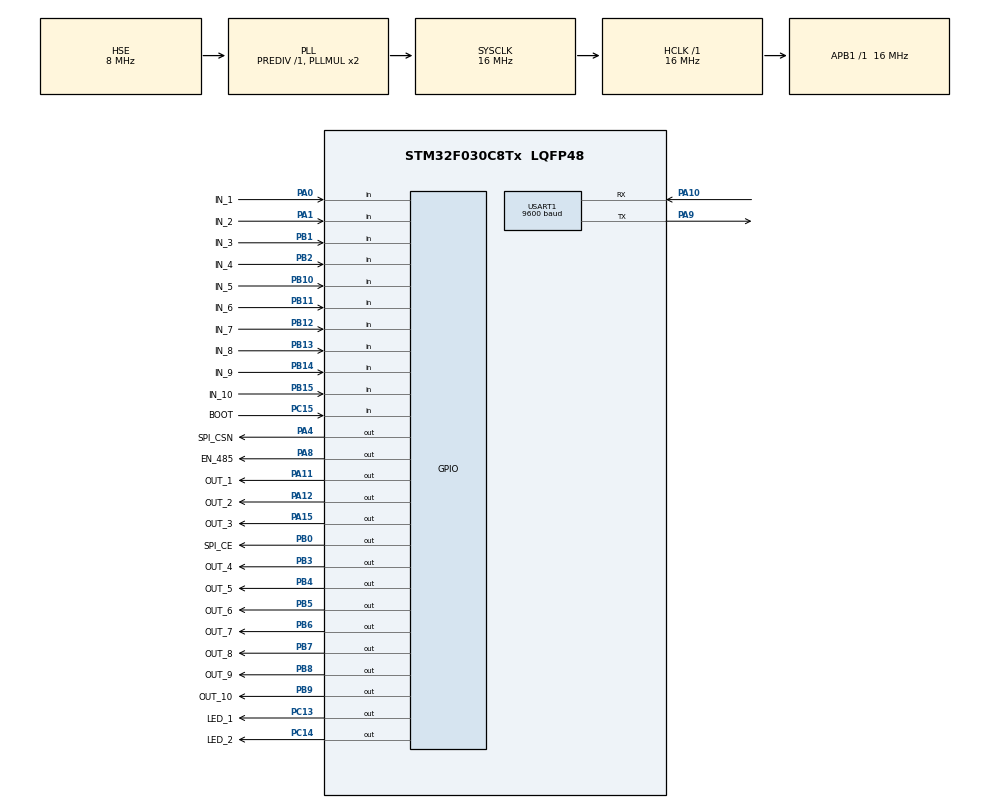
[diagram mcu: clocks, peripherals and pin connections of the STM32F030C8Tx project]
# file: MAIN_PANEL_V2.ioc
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Dma.Request0=USART1_RX
Dma.USART1_RX.0.Direction=DMA_PERIPH_TO_MEMORY
Dma.USART1_RX.0.Instance=DMA1_Channel3
Dma.USART1_RX.0.MemDataAlignment=DMA_MDATAALIGN_BYTE
Dma.USART1_RX.0.MemInc=DMA_MINC_ENABLE
Dma.USART1_RX.0.Mode=DMA_CIRCULAR
Dma.USART1_RX.0.PeriphDataAlignment=DMA_PDATAALIGN_BYTE
Dma.USART1_RX.0.PeriphInc=DMA_PINC_DISABLE
Dma.USART1_RX.0.Priority=DMA_PRIORITY_LOW
Mcu.Family=STM32F0
Mcu.Name=STM32F030C8Tx
Mcu.Package=LQFP48
NVIC.DMA1_Channel2_3_IRQn=true\:0\:0\:false\:false\:true\:false\:true\:true
NVIC.TIM14_IRQn=true\:3\:0\:true\:false\:true\:true\:true\:true
NVIC.TIM6_IRQn=true\:3\:0\:true\:false\:true\:true\:true\:true
PA0.GPIO_Label=IN_1
PA0.GPIO_PuPd=GPIO_PULLDOWN
PA0.Signal=GPIO_Input
PA1.GPIO_Label=IN_2
PA1.GPIO_PuPd=GPIO_PULLDOWN
PA1.Signal=GPIO_Input
PA10.Mode=Asynchronous
PA10.Signal=USART1_RX
PA11.GPIO_Label=OUT_1
PA11.GPIO_PuPd=GPIO_PULLDOWN
PA11.Signal=GPIO_Output
PA12.GPIO_Label=OUT_2
PA12.GPIO_PuPd=GPIO_PULLDOWN
PA12.Signal=GPIO_Output
PA13.Mode=Serial_Wire
PA13.Signal=SYS_SWDIO
PA14.Mode=Serial_Wire
PA14.Signal=SYS_SWCLK
PA15.GPIO_Label=OUT_3
PA15.GPIO_PuPd=GPIO_PULLDOWN
PA15.Signal=GPIO_Output
PA4.GPIO_Label=SPI_CSN
PA4.Signal=GPIO_Output
PA8.GPIO_Label=EN_485
PA8.GPIO_PuPd=GPIO_PULLDOWN
PA8.Signal=GPIO_Output
PA9.Mode=Asynchronous
PA9.Signal=USART1_TX
PB0.GPIO_Label=SPI_CE
PB0.Signal=GPIO_Output
PB1.GPIO_Label=IN_3
PB1.GPIO_PuPd=GPIO_PULLDOWN
PB1.Signal=GPIO_Input
PB10.GPIO_Label=IN_5
PB10.GPIO_PuPd=GPIO_PULLDOWN
PB10.Signal=GPIO_Input
PB11.GPIO_Label=IN_6
PB11.GPIO_PuPd=GPIO_PULLDOWN
PB11.Signal=GPIO_Input
PB12.GPIO_Label=IN_7
PB12.GPIO_PuPd=GPIO_PULLDOWN
PB12.Signal=GPIO_Input
PB13.GPIO_Label=IN_8
PB13.GPIO_PuPd=GPIO_PULLDOWN
PB13.Signal=GPIO_Input
PB14.GPIO_Label=IN_9
PB14.GPIO_PuPd=GPIO_PULLDOWN
PB14.Signal=GPIO_Input
PB15.GPIO_Label=IN_10
PB15.GPIO_PuPd=GPIO_PULLDOWN
PB15.Signal=GPIO_Input
PB2.GPIO_Label=IN_4
PB2.GPIO_PuPd=GPIO_PULLDOWN
PB2.Signal=GPIO_Input
PB3.GPIO_Label=OUT_4
PB3.GPIO_PuPd=GPIO_PULLDOWN
PB3.Signal=GPIO_Output
PB4.GPIO_Label=OUT_5
PB4.GPIO_PuPd=GPIO_PULLDOWN
PB4.Signal=GPIO_Output
PB5.GPIO_Label=OUT_6
PB5.GPIO_PuPd=GPIO_PULLDOWN
PB5.Signal=GPIO_Output
PB6.GPIO_Label=OUT_7
PB6.GPIO_PuPd=GPIO_PULLDOWN
PB6.Signal=GPIO_Output
PB7.GPIO_Label=OUT_8
PB7.GPIO_PuPd=GPIO_PULLDOWN
PB7.Signal=GPIO_Output
PB8.GPIO_Label=OUT_9
PB8.GPIO_PuPd=GPIO_PULLDOWN
PB8.Signal=GPIO_Output
PB9.GPIO_Label=OUT_10
PB9.GPIO_PuPd=GPIO_PULLDOWN
PB9.Signal=GPIO_Output
PC13.GPIO_Label=LED_1
PC13.GPIO_ModeDefaultOutputPP=GPIO_MODE_OUTPUT_OD
PC13.GPIO_PuPd=GPIO_PULLUP
PC13.Signal=GPIO_Output
PC14-OSC32_IN.GPIO_Label=LED_2
PC14-OSC32_IN.GPIO_ModeDefaultOutputPP=GPIO_MODE_OUTPUT_OD
PC14-OSC32_IN.GPIO_PuPd=GPIO_PULLUP
PC14-OSC32_IN.Signal=GPIO_Output
PC15-OSC32_OUT.GPIO_Label=BOOT
PC15-OSC32_OUT.GPIO_PuPd=GPIO_PULLUP
PC15-OSC32_OUT.Signal=GPIO_Input
PF0-OSC_IN.Mode=HSE-External-Oscillator
PF0-OSC_IN.Signal=RCC_OSC_IN
PF1-OSC_OUT.Mode=HSE-External-Oscillator
PF1-OSC_OUT.Signal=RCC_OSC_OUT
ProjectManager.HeapSize=0x200
ProjectManager.StackSize=0x400
ProjectManager.TargetToolchain=EWARM V8.32
RCC.AHBFreq_Value=16000000
RCC.APB1Freq_Value=16000000
RCC.APB1TimFreq_Value=16000000
RCC.HCLKFreq_Value=16000000
RCC.I2c1ClockSelection=RCC_I2C1CLKSOURCE_SYSCLK
RCC.PLLSourceVirtual=RCC_PLLSOURCE_HSE
RCC.SYSCLKFreq_VALUE=16000000
RCC.SYSCLKSource=RCC_SYSCLKSOURCE_PLLCLK
TIM14.AutoReloadPreload=TIM_AUTORELOAD_PRELOAD_ENABLE
TIM14.Period=999
TIM14.Prescaler=16000
TIM6.AutoReloadPreload=TIM_AUTORELOAD_PRELOAD_ENABLE
TIM6.Period=999
TIM6.Prescaler=16000
USART1.BaudRate=9600
USART1.OverrunDisableParam=ADVFEATURE_OVERRUN_ENABLE
USART1.VirtualMode-Asynchronous=VM_ASYNC
VP_TIM14_VS_ClockSourceINT.Mode=Enable_Timer
VP_TIM6_VS_ClockSourceINT.Mode=Enable_Timer
board=custom

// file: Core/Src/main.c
/* USER CODE BEGIN Header */
/**
  ******************************************************************************
  * @file           : main.c
  * @brief          : Main program body
  ******************************************************************************
  * @attention
  *
  * Copyright (c) 2023 STMicroelectronics.
  * All rights reserved.
  *
  * This software is licensed under terms that can be found in the LICENSE file
  * in the root directory of this software component.
  * If no LICENSE file comes with this software, it is provided AS-IS.
  *
  ******************************************************************************
  */
/* USER CODE END Header */
#include "main.h"

/* USER CODE BEGIN Includes */
#include "AppInterface.h"
/* USER CODE END Includes */

TIM_HandleTypeDef htim6;
TIM_HandleTypeDef htim14;

UART_HandleTypeDef huart1;
DMA_HandleTypeDef hdma_usart1_rx;

void SystemClock_Config(void);
static void MX_GPIO_Init(void);
static void MX_DMA_Init(void);
static void MX_USART1_UART_Init(void);
static void MX_TIM6_Init(void);
static void MX_TIM14_Init(void);

int main(void)
{

  /* MCU Configuration--------------------------------------------------------*/

  /* Reset of all peripherals, Initializes the Flash interface and the Systick. */
  HAL_Init();

  /* Configure the system clock */
  SystemClock_Config();

  /* Initialize all configured peripherals */
  MX_GPIO_Init();
  MX_DMA_Init();
  MX_USART1_UART_Init();
  MX_TIM6_Init();
  MX_TIM14_Init();
  /* USER CODE BEGIN 2 */
  AppReadDataOption();
  TimerAction(&htim14, TIMER_INTERRUPT, TIMER_START);

  /* USER CODE END 2 */

  /* Infinite loop */
  while (1)
  {

    /* USER CODE BEGIN 3 */
    AppCycleCheckBootPin();
    AppUartCycleUpdateIOValue();
    AppCycleGetInputDataPin();
    AppCycleSetLedStatus();
    /*Check Time for reboot system*/
    CheckTimeEnterReboot();
  }
  /* USER CODE END 3 */
}

void SystemClock_Config(void)
{
  RCC_OscInitTypeDef RCC_OscInitStruct = {0};
  RCC_ClkInitTypeDef RCC_ClkInitStruct = {0};
  RCC_PeriphCLKInitTypeDef PeriphClkInit = {0};

  /** Initializes the RCC Oscillators according to the specified parameters
  * in the RCC_OscInitTypeDef structure.
  */
  RCC_OscInitStruct.OscillatorType = RCC_OSCILLATORTYPE_HSE;
  RCC_OscInitStruct.HSEState = RCC_HSE_ON;
  RCC_OscInitStruct.PLL.PLLState = RCC_PLL_ON;
  RCC_OscInitStruct.PLL.PLLSource = RCC_PLLSOURCE_HSE;
  RCC_OscInitStruct.PLL.PLLMUL = RCC_PLL_MUL2;
  RCC_OscInitStruct.PLL.PREDIV = RCC_PREDIV_DIV1;
  if (HAL_RCC_OscConfig(&RCC_OscInitStruct) != HAL_OK)
  {
    Error_Handler();
  }

  /** Initializes the CPU, AHB and APB buses clocks
  */
  RCC_ClkInitStruct.ClockType = RCC_CLOCKTYPE_HCLK|RCC_CLOCKTYPE_SYSCLK
                              |RCC_CLOCKTYPE_PCLK1;
  RCC_ClkInitStruct.SYSCLKSource = RCC_SYSCLKSOURCE_PLLCLK;
  RCC_ClkInitStruct.AHBCLKDivider = RCC_SYSCLK_DIV1;
  RCC_ClkInitStruct.APB1CLKDivider = RCC_HCLK_DIV1;

  if (HAL_RCC_ClockConfig(&RCC_ClkInitStruct, FLASH_LATENCY_0) != HAL_OK)
  {
    Error_Handler();
  }
  PeriphClkInit.PeriphClockSelection = RCC_PERIPHCLK_USART1;
  PeriphClkInit.Usart1ClockSelection = RCC_USART1CLKSOURCE_PCLK1;
  if (HAL_RCCEx_PeriphCLKConfig(&PeriphClkInit) != HAL_OK)
  {
    Error_Handler();
  }
}

static void MX_TIM6_Init(void)
{

  htim6.Instance = TIM6;
  htim6.Init.Prescaler = 16000;
  htim6.Init.CounterMode = TIM_COUNTERMODE_UP;
  htim6.Init.Period = 999;
  htim6.Init.AutoReloadPreload = TIM_AUTORELOAD_PRELOAD_ENABLE;
  if (HAL_TIM_Base_Init(&htim6) != HAL_OK)
  {
    Error_Handler();
  }

}

static void MX_TIM14_Init(void)
{

  htim14.Instance = TIM14;
  htim14.Init.Prescaler = 16000;
  htim14.Init.CounterMode = TIM_COUNTERMODE_UP;
  htim14.Init.Period = 999;
  htim14.Init.ClockDivision = TIM_CLOCKDIVISION_DIV1;
  htim14.Init.AutoReloadPreload = TIM_AUTORELOAD_PRELOAD_ENABLE;
  if (HAL_TIM_Base_Init(&htim14) != HAL_OK)
  {
    Error_Handler();
  }

}

static void MX_USART1_UART_Init(void)
{

  huart1.Instance = USART1;
  huart1.Init.BaudRate = 9600;
  huart1.Init.WordLength = UART_WORDLENGTH_8B;
  huart1.Init.StopBits = UART_STOPBITS_1;
  huart1.Init.Parity = UART_PARITY_NONE;
  huart1.Init.Mode = UART_MODE_TX_RX;
  huart1.Init.HwFlowCtl = UART_HWCONTROL_NONE;
  huart1.Init.OverSampling = UART_OVERSAMPLING_16;
  huart1.Init.OneBitSampling = UART_ONE_BIT_SAMPLE_DISABLE;
  huart1.AdvancedInit.AdvFeatureInit = UART_ADVFEATURE_NO_INIT;
  if (HAL_UART_Init(&huart1) != HAL_OK)
  {
    Error_Handler();
  }

}

static void MX_DMA_Init(void)
{

  /* DMA controller clock enable */
  __HAL_RCC_DMA1_CLK_ENABLE();

  /* DMA interrupt init */
  /* DMA1_Channel2_3_IRQn interrupt configuration */
  HAL_NVIC_SetPriority(DMA1_Channel2_3_IRQn, 0, 0);
  HAL_NVIC_EnableIRQ(DMA1_Channel2_3_IRQn);

}

static void MX_GPIO_Init(void)
{
  GPIO_InitTypeDef GPIO_InitStruct = {0};

  /* GPIO Ports Clock Enable */
  __HAL_RCC_GPIOC_CLK_ENABLE();
  __HAL_RCC_GPIOF_CLK_ENABLE();
  __HAL_RCC_GPIOA_CLK_ENABLE();
  __HAL_RCC_GPIOB_CLK_ENABLE();

  /*Configure GPIO pin Output Level */
  HAL_GPIO_WritePin(GPIOC, LED_1_Pin|LED_2_Pin, GPIO_PIN_RESET);

  /*Configure GPIO pin Output Level */
  HAL_GPIO_WritePin(GPIOA, SPI_CSN_Pin|EN_485_Pin|OUT_1_Pin|OUT_2_Pin
                          |OUT_3_Pin, GPIO_PIN_RESET);

  /*Configure GPIO pin Output Level */
  HAL_GPIO_WritePin(GPIOB, SPI_CE_Pin|OUT_4_Pin|OUT_5_Pin|OUT_6_Pin
                          |OUT_7_Pin|OUT_8_Pin|OUT_9_Pin|OUT_10_Pin, GPIO_PIN_RESET);

  /*Configure GPIO pins : LED_1_Pin LED_2_Pin */
  GPIO_InitStruct.Pin = LED_1_Pin|LED_2_Pin;
  GPIO_InitStruct.Mode = GPIO_MODE_OUTPUT_OD;
  GPIO_InitStruct.Pull = GPIO_PULLUP;
  GPIO_InitStruct.Speed = GPIO_SPEED_FREQ_LOW;
  HAL_GPIO_Init(GPIOC, &GPIO_InitStruct);

  /*Configure GPIO pin : BOOT_Pin */
  GPIO_InitStruct.Pin = BOOT_Pin;
  GPIO_InitStruct.Mode = GPIO_MODE_INPUT;
  GPIO_InitStruct.Pull = GPIO_PULLUP;
  HAL_GPIO_Init(BOOT_GPIO_Port, &GPIO_InitStruct);

  /*Configure GPIO pins : IN_1_Pin IN_2_Pin */
  GPIO_InitStruct.Pin = IN_1_Pin|IN_2_Pin;
  GPIO_InitStruct.Mode = GPIO_MODE_INPUT;
  GPIO_InitStruct.Pull = GPIO_PULLDOWN;
  HAL_GPIO_Init(GPIOA, &GPIO_InitStruct);

  /*Configure GPIO pin : SPI_CSN_Pin */
  GPIO_InitStruct.Pin = SPI_CSN_Pin;
  GPIO_InitStruct.Mode = GPIO_MODE_OUTPUT_PP;
  GPIO_InitStruct.Pull = GPIO_NOPULL;
  GPIO_InitStruct.Speed = GPIO_SPEED_FREQ_LOW;
  HAL_GPIO_Init(SPI_CSN_GPIO_Port, &GPIO_InitStruct);

  /*Configure GPIO pin : SPI_CE_Pin */
  GPIO_InitStruct.Pin = SPI_CE_Pin;
  GPIO_InitStruct.Mode = GPIO_MODE_OUTPUT_PP;
  GPIO_InitStruct.Pull = GPIO_NOPULL;
  GPIO_InitStruct.Speed = GPIO_SPEED_FREQ_LOW;
  HAL_GPIO_Init(SPI_CE_GPIO_Port, &GPIO_InitStruct);

  /*Configure GPIO pins : IN_3_Pin IN_4_Pin IN_5_Pin IN_6_Pin
                           IN_7_Pin IN_8_Pin IN_9_Pin IN_10_Pin */
  GPIO_InitStruct.Pin = IN_3_Pin|IN_4_Pin|IN_5_Pin|IN_6_Pin
                          |IN_7_Pin|IN_8_Pin|IN_9_Pin|IN_10_Pin;
  GPIO_InitStruct.Mode = GPIO_MODE_INPUT;
  GPIO_InitStruct.Pull = GPIO_PULLDOWN;
  HAL_GPIO_Init(GPIOB, &GPIO_InitStruct);

  /*Configure GPIO pins : EN_485_Pin OUT_1_Pin OUT_2_Pin OUT_3_Pin */
  GPIO_InitStruct.Pin = EN_485_Pin|OUT_1_Pin|OUT_2_Pin|OUT_3_Pin;
  GPIO_InitStruct.Mode = GPIO_MODE_OUTPUT_PP;
  GPIO_InitStruct.Pull = GPIO_PULLDOWN;
  GPIO_InitStruct.Speed = GPIO_SPEED_FREQ_LOW;
  HAL_GPIO_Init(GPIOA, &GPIO_InitStruct);

  /*Configure GPIO pins : OUT_4_Pin OUT_5_Pin OUT_6_Pin OUT_7_Pin
                           OUT_8_Pin OUT_9_Pin OUT_10_Pin */
  GPIO_InitStruct.Pin = OUT_4_Pin|OUT_5_Pin|OUT_6_Pin|OUT_7_Pin
                          |OUT_8_Pin|OUT_9_Pin|OUT_10_Pin;
  GPIO_InitStruct.Mode = GPIO_MODE_OUTPUT_PP;
  GPIO_InitStruct.Pull = GPIO_PULLDOWN;
  GPIO_InitStruct.Speed = GPIO_SPEED_FREQ_LOW;
  HAL_GPIO_Init(GPIOB, &GPIO_InitStruct);

}

void Error_Handler(void)
{
  __disable_irq();
  while (1)
  {
  }
}
